# GD32H77x register map
File version: 1.0
CPU: CM7 r1p2, little endian, MPU, FPU, 4 interrupt priority bits
Registers are 32-bit, read-write, reset 0x0 unless marked. A register's access mark holds for its fields unless they carry their own. Offsets are from the block's base; [hi:lo] are bit positions.

## PMU — Power management unit
Base 0x58005800
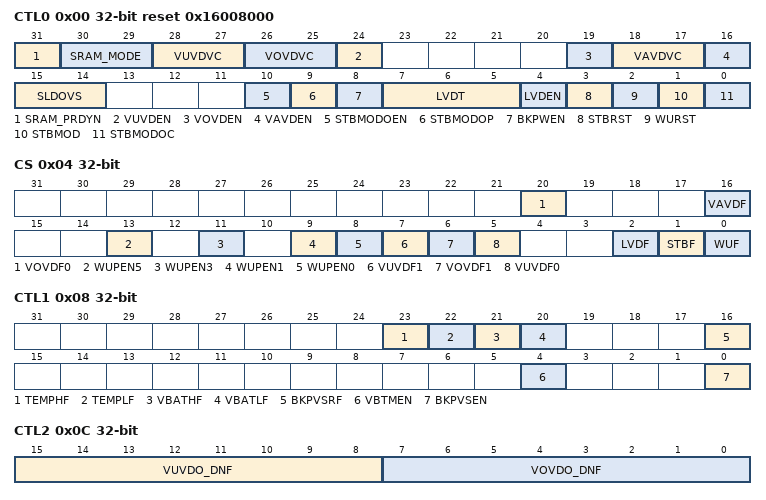
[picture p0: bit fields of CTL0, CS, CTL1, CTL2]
0x00 CTL0 access per field reset 0x16008000 — Control register 0
  [31] SRAM_PRDYN ro — Indicates when the internal memory instance power supplies are stable after returning from retention mode.
  [30:29] SRAM_MODE rw — Sram_mode in Deep-sleep
  [28:27] VUVDVC rw — V0.9V under voltage detector voltage level configure bits
  [26:25] VOVDVC rw — V0.9V over voltage detector voltage level configure bits.
  [24] VUVDEN rw — V0.9V under voltage detector enable
  [19] VOVDEN rw — V0.9V over voltage detector voltage level enable bit
  [18:17] VAVDVC rw — VDDA analog voltage detector voltage level configure bits
  [16] VAVDEN rw — VDDA analog voltage detector voltage enable bit
  [15:14] SLDOVS rw — Deep-sleep mode voltage scaling selection
  [10] STBMODOEN rw — Standby state output enable selection
  [9] STBMODOP rw — Standby state output polarity enable selection ( Standby mode output from PC7 )
  [8] BKPWEN rw — Backup domain write enable bit
  [7:5] LVDT rw — Low voltage detector threshold
  [4] LVDEN rw — Low voltage detector enable bit
  [3] STBRST rw — Standby flag reset bit
  [2] WURST rw — Wakeup flag reset bit
  [1] STBMOD rw — Standby Mode
  [0] STBMODOC rw — Standby state Off-chip output enable selection
0x04 CS access per field — Control and status register
  [20] VOVDF0 ro — Peripheral voltage on V0.9V detector flag bit
  [16] VAVDF ro — Analog voltage detector output on VDDA
  [13] WUPEN5 rw — WKUP Pin5 (PC1) enable
  [11] WUPEN3 rw — WKUP pin3 (PC13) enable
  [9] WUPEN1 rw — WKUP pin1 (PA2) enable
  [8] WUPEN0 rw — WKUP pin0 (PA0) enable
  [7] VUVDF1 ro — V0.9V under voltage detector flag bit after digital filter
  [6] VOVDF1 ro — V0.9V over voltage detector flag bit after digital filter
  [5] VUVDF0 ro — V0.9V under voltage detector flag bit
  [2] LVDF ro — Low voltage detector status flag
  [1] STBF ro — Standby flag
  [0] WUF ro — Wakeup Flag
0x08 CTL1 access per field — Control register 1
  [23] TEMPHF ro — Temperature level monitoring versus high threshold
  [22] TEMPLF ro — Temperature level monitoring versus low threshold
  [21] VBATHF ro — VBAT level monitoring versus high threshold
  [20] VBATLF ro — VBAT level monitoring versus low threshold
  [16] BKPVSRF ro — Backup voltage stabilizer ready flag
  [4] VBTMEN rw — VBAT and temperature monitoring enable.
  [0] BKPVSEN rw — Backup voltage stabilizer enable
0x0C CTL2 — Control register 2
  [15:8] VUVDO_DNF — VUVD analog output digital noise filter
  [7:0] VOVDO_DNF — VOVD analog output digital noise filter
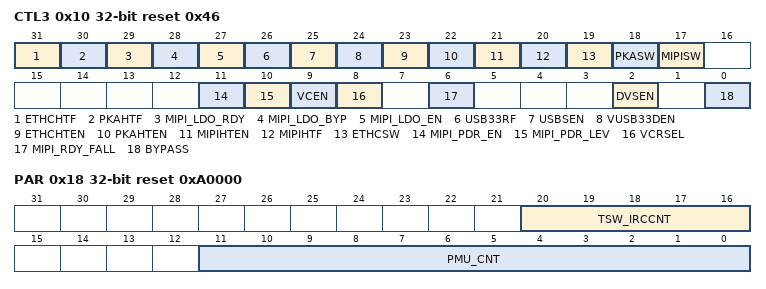
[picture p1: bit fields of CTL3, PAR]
0x10 CTL3 access per field reset 0x46 — Control register 3
  [31] ETHCHTF ro — ETHC power switch ack flag
  [30] PKAHTF ro — PKA power switch ack flag
  [29] MIPI_LDO_RDY ro — The MIPI_LDO output voltage ready signal
  [28] MIPI_LDO_BYP rw — MIPI_LDO BYPASS mode enable signal
  [27] MIPI_LDO_EN rw — MIPI_LDO enable signal
  [26] USB33RF ro — USB supply ready flag bit
  [25] USBSEN rw — USB voltage stabilizer enable.
  [24] VUSB33DEN rw — VDD33USB voltage level detector enable bit
  [23] ETHCHTEN rw — ETHC output isolation enable
  [22] PKAHTEN rw — PKA output isolation enable
  [21] MIPIHTEN rw — MIPI output isolation enable
  [20] MIPIHTF ro — Mipi power switch ack flag
  [19] ETHCSW rw — Powers off the ETHC.
  [18] PKASW rw — Powers off the PKA.
  [17] MIPISW rw — Powers off the MIPI.
  [11] MIPI_PDR_EN rw — MIPI_LDO VDD09DSI PDR function enable signal.
  [10] MIPI_PDR_LEV rw — MIPI_LDO VDD09DSI PDR threshold selection control signal.
  [9] VCEN rw — VBAT battery charging enable
  [8] VCRSEL rw — VBAT battery charging resistor selection
  [6] MIPI_RDY_FALL rw — The A2D_MIPI_LDO_RDY signal performs falling edge detection
  [2] DVSEN rw — Step-down voltage stabilizer enable bit
  [0] BYPASS rw — Power management unit bypass control bit
0x18 PAR reset 0xA0000 — Parameter register
  [20:16] TSW_IRCCNT — switch to LPIRC4M / IRC64M (confirmed by DSPWUSSEL) clock
  [11:0] PMU_CNT — Exit Deep-sleep mode wait time count configure bits
